# MPS2_SSE_200 register map
Vendor: ARM Ltd.; Series: ARMv8-M Mainline; File version: 1.0
CPU: CM33 r0p0, little endian, MPU, no FPU, 4 interrupt priority bits, 8 SAU regions
Registers are 32-bit, read-write, reset 0x0 unless marked. A register's access mark holds for its fields unless they carry their own. Offsets are from the block's base; [hi:lo] are bit positions; {n}, {i} and the like mark numbered series; 'fields as' and 'values as' point back to an identical list.

## SAU — Security Attribution Unit
Base 0xE000EDD0
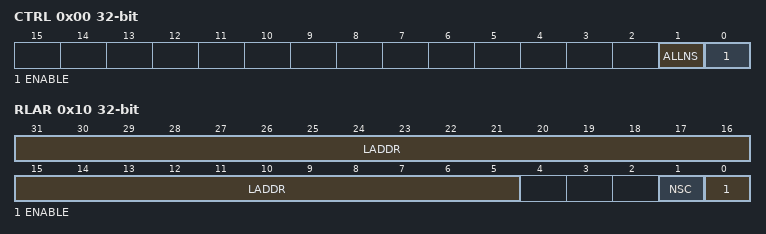
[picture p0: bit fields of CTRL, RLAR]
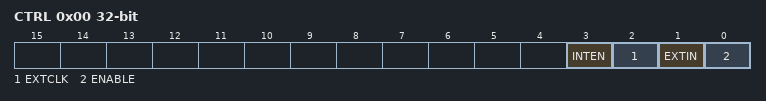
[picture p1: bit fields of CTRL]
0x00 CTRL — Control Register
  [1] ALLNS — Security attribution if SAU disabled
    0=Secure (Memory is marked as secure); 1=Non_Secure (Memory is marked as non-secure)
  [0] ENABLE
    0=Disable (SAU is disabled); 1=Enable (SAU is enabled)
0x04 TYPE ro
  [7:0] SREGION — Number of implemented SAU regions
0x08 RNR — Region Number Register
  [7:0] REGION — Currently selected SAU region
    {v}=SAU_Region_{v} (Select SAU Region {v}) (v=0..3)
0x0C RBAR — Region Base Address Register
  [31:5] BADDR — Base Address
0x10 RLAR — Region Limit Address Register
  [31:5] LADDR — Limit Address
  [1] NSC — Non-Secure Callable
  [0] ENABLE — SAU Region enabled

## TIMER0
Base 0x40000000
Same registers: TIMER1 0x40001000, S32KTIMER 0x4002F000, TIMER0_Secure 0x50000000, TIMER1_Secure 0x50001000
0x00 CTRL — Control Register
  [3] INTEN — Interrupt Enable
    0=Disable (Interrupt is disabled); 1=Enable (Interrupt is enabled)
  [2] EXTCLK — External Clock Enable
    0=Disable (External Clock is disabled); 1=Enable (External Clock is enabled)
  [1] EXTIN — External Input as Enable
    0=Disable (External Input as Enable is disabled); 1=Enable (External Input as Enable is enabled)
  [0] ENABLE
    0=Disable (Timer is disabled); 1=Enable (Timer is enabled)
0x04 VALUE — Current Timer Counter Value
0x08 RELOAD — Counter Reload Value
0x0C INTSTATUS ro — Timer Interrupt status register
0x0C INTCLEAR wo write-1-clears (alternate view of INTSTATUS) — Timer Interrupt clear register

## DUALTIMER
Base 0x40002000
Same registers: DUALTIMER_Secure 0x50002000
0x00 TIMER1LOAD
0x04 TIMER1VALUE ro reset 0xFFFFFFFF
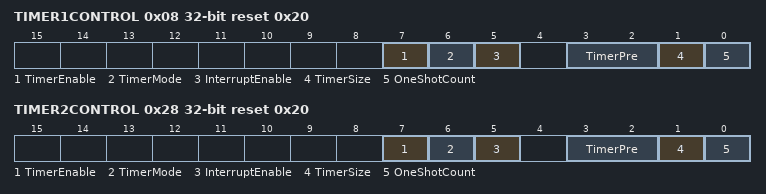
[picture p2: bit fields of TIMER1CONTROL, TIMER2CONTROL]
0x08 TIMER1CONTROL reset 0x20
  [7] TimerEnable — Timer Enable Enable bit.
    0=Disable (Timer is disabled.); 1=Enable (Timer is enabled.)
  [6] TimerMode — Timer Mode bit.
    0=Free-Running timer mode; 1=Periodic timer mode
  [5] InterruptEnable — Interrupt Enable bit.
    0=Disable (Interrupt is disabled.); 1=Enable (Interrupt is enabled.)
  [3:2] TimerPre — Timer prescale bits.
    0=divided by 1 (clock is divided by 1); 1=divided by 16 (clock is divided by 16); 2=divided by 256 (clock is divided by 256)
  [1] TimerSize — Selects 16-bit or 32- bit counter operation.
    0=16-bit counter mode; 1=32-bit counter mode
  [0] OneShotCount — Selects one-shot or wrapping counter mode.
    0=Wrapping counter mode; 1=One-shot counter mode
0x0C TIMER1INTCLR wo — Timer 1 Interrupt Clear Register
  [0] INT write-1-clears — Interrupt
0x10 TIMER1RIS ro — Timer 1 Raw Interrupt Status Register
  [0] RIS — Raw Timer Interrupt
0x14 TIMER1MIS ro — Timer 1 Mask Interrupt Status Register
  [0] MIS — Masked Timer Interrupt
0x18 TIMER1BGLOAD — Timer 1 Background Load Register
0x20 TIMER2LOAD
0x24 TIMER2VALUE ro reset 0xFFFFFFFF
0x28 TIMER2CONTROL reset 0x20
  fields as TIMER1CONTROL
0x2C TIMER2INTCLR wo — Timer 2 Interrupt Clear Register
  [0] INT write-1-clears — Interrupt
0x30 TIMER2RIS ro — Timer 2 Raw Interrupt Status Register
  [0] RIS — Raw Timer Interrupt
0x34 TIMER2MIS ro — Timer 2 Mask Interrupt Status Register
  [0] MIS — Masked Timer Interrupt
0x38 TIMER2BGLOAD — Timer 2 Background Load Register

## UART0
Base 0x40200000
Same registers: UART2 0x02656F10, UART1 0x40201000, UART3 0x40203000, UART4 0x40204000, UART0_Secure 0x50200000, UART1_Secure 0x50201000, UART2_Secure 0x50202000, UART3_Secure 0x50203000, UART4_Secure 0x50204000
0x00 DATA 8-bit — Receive and Transmit Data Value
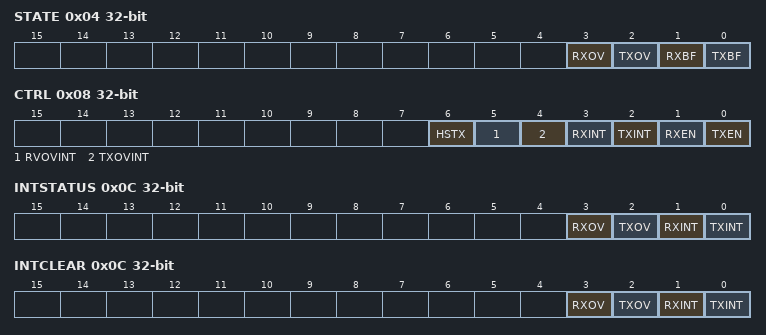
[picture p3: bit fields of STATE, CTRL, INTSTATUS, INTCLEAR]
0x04 STATE — UART Status Register
  [3] RXOV write-1-clears — RX Buffer Overun (write 1 to clear)
  [2] TXOV write-1-clears — TX Buffer Overun (write 1 to clear)
  [1] RXBF ro — RX Buffer Full
  [0] TXBF ro — TX Buffer Full
0x08 CTRL — UART Control Register
  [all] fields
    0=Disabled; 1=Enabled
  [6] HSTX — High Speed Test Mode for TX only
  [5] RVOVINT — RX Overrun Interrupt Enable
  [4] TXOVINT — TX Overrun Interrupt Enable
  [3] RXINT — RX Interrupt Enable
  [2] TXINT — TX Interrupt Enable
  [1] RXEN — RX Enable
  [0] TXEN — TX Enable
0x0C INTSTATUS ro — UART Interrupt Status Register
  [3] RXOV — RX Overrun Interrupt
  [2] TXOV — TX Overrun Interrupt
  [1] RXINT — RX Interrupt
  [0] TXINT — TX Interrupt
0x0C INTCLEAR wo (alternate view of INTSTATUS) — UART Interrupt CLEAR Register
  [3] RXOV write-1-clears — RX Overrun Interrupt
  [2] TXOV write-1-clears — TX Overrun Interrupt
  [1] RXINT write-1-clears — RX Interrupt
  [0] TXINT write-1-clears — TX Interrupt
0x10 BAUDDIV — Baudrate Divider
